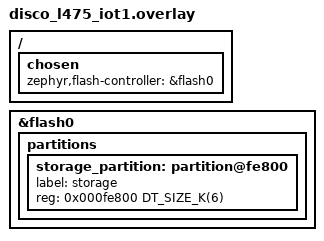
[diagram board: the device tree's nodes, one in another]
/*
 * Copyright (c) 2022 STMicroelectronics
 *
 * SPDX-License-Identifier: Apache-2.0
 */


/delete-node/ &scratch_partition;
/delete-node/ &storage_partition;

/ {
	chosen {
		zephyr,flash-controller = &flash0;
	};
};

&flash0 {
	partitions {
		/* Set 6Kb of storage at the end of the 1Mb of flash */
		storage_partition: partition@fe800 {
			label = "storage";
			reg = <0x000fe800 DT_SIZE_K(6)>;
		};
	};
};
